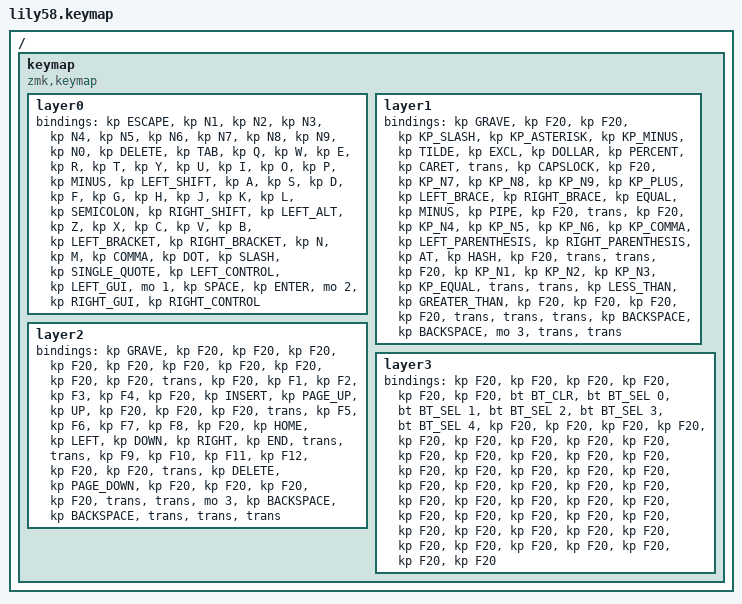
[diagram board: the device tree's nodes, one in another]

  /*
  * Copyright (c) 2020 The ZMK Contributors
  *
  * SPDX-License-Identifier: MIT
  */

  #include <behaviors.dtsi>
  #include <dt-bindings/zmk/keys.h>
  #include <dt-bindings/zmk/bt.h>
  #include <dt-bindings/zmk/ext_power.h>

  / {
    keymap {
      compatible = "zmk,keymap";
  layer0 {
          bindings = <
          &kp ESCAPE &kp N1 &kp N2 &kp N3 &kp N4 &kp N5 &kp N6 &kp N7 &kp N8 &kp N9 &kp N0 &kp DELETE &kp TAB &kp Q &kp W &kp E &kp R &kp T &kp Y &kp U &kp I &kp O &kp P &kp MINUS &kp LEFT_SHIFT &kp A &kp S &kp D &kp F &kp G &kp H &kp J &kp K &kp L &kp SEMICOLON &kp RIGHT_SHIFT &kp LEFT_ALT &kp Z &kp X &kp C &kp V &kp B &kp LEFT_BRACKET &kp RIGHT_BRACKET &kp N &kp M &kp COMMA &kp DOT &kp SLASH &kp SINGLE_QUOTE &kp LEFT_CONTROL &kp LEFT_GUI &mo 1 &kp SPACE &kp ENTER &mo 2 &kp RIGHT_GUI &kp RIGHT_CONTROL
          >;
        };layer1 {
          bindings = <
          &kp GRAVE &kp F20 &kp F20 &kp KP_SLASH &kp KP_ASTERISK &kp KP_MINUS &kp TILDE &kp EXCL &kp DOLLAR &kp PERCENT &kp CARET &trans &kp CAPSLOCK &kp F20 &kp KP_N7 &kp KP_N8 &kp KP_N9 &kp KP_PLUS &kp LEFT_BRACE &kp RIGHT_BRACE &kp EQUAL &kp MINUS &kp PIPE &kp F20 &trans &kp F20 &kp KP_N4 &kp KP_N5 &kp KP_N6 &kp KP_COMMA &kp LEFT_PARENTHESIS &kp RIGHT_PARENTHESIS &kp AT &kp HASH &kp F20 &trans &trans &kp F20 &kp KP_N1 &kp KP_N2 &kp KP_N3 &kp KP_EQUAL &trans &trans &kp LESS_THAN &kp GREATER_THAN &kp F20 &kp F20 &kp F20 &kp F20 &trans &trans &trans &kp BACKSPACE &kp BACKSPACE &mo 3 &trans &trans
          >;
        };layer2 {
          bindings = <
          &kp GRAVE &kp F20 &kp F20 &kp F20 &kp F20 &kp F20 &kp F20 &kp F20 &kp F20 &kp F20 &kp F20 &trans &kp F20 &kp F1 &kp F2 &kp F3 &kp F4 &kp F20 &kp INSERT &kp PAGE_UP &kp UP &kp F20 &kp F20 &kp F20 &trans &kp F5 &kp F6 &kp F7 &kp F8 &kp F20 &kp HOME &kp LEFT &kp DOWN &kp RIGHT &kp END &trans &trans &kp F9 &kp F10 &kp F11 &kp F12 &kp F20 &kp F20 &trans &kp DELETE &kp PAGE_DOWN &kp F20 &kp F20 &kp F20 &kp F20 &trans &trans &mo 3 &kp BACKSPACE &kp BACKSPACE &trans &trans &trans
          >;
        };layer3 {
          bindings = <
          &kp F20 &kp F20 &kp F20 &kp F20 &kp F20 &kp F20 &bt BT_CLR &bt BT_SEL 0 &bt BT_SEL 1 &bt BT_SEL 2 &bt BT_SEL 3 &bt BT_SEL 4 &kp F20 &kp F20 &kp F20 &kp F20 &kp F20 &kp F20 &kp F20 &kp F20 &kp F20 &kp F20 &kp F20 &kp F20 &kp F20 &kp F20 &kp F20 &kp F20 &kp F20 &kp F20 &kp F20 &kp F20 &kp F20 &kp F20 &kp F20 &kp F20 &kp F20 &kp F20 &kp F20 &kp F20 &kp F20 &kp F20 &kp F20 &kp F20 &kp F20 &kp F20 &kp F20 &kp F20 &kp F20 &kp F20 &kp F20 &kp F20 &kp F20 &kp F20 &kp F20 &kp F20 &kp F20 &kp F20
          >;
        };
    };
  };
  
